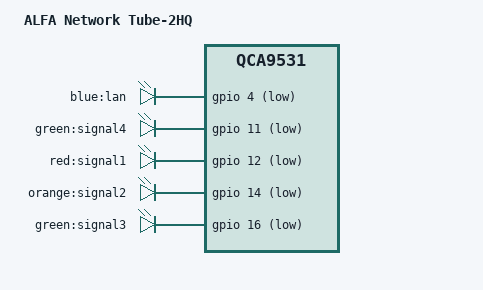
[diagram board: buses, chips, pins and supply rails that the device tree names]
// SPDX-License-Identifier: GPL-2.0-or-later OR MIT

#include "qca9531_alfa-network_r36a.dtsi"

/ {
	model = "ALFA Network Tube-2HQ";
	compatible = "alfa-network,tube-2hq", "qca,qca9531";

	aliases {
		led-boot = &led_signal4;
		led-failsafe = &led_signal4;
		led-upgrade = &led_signal4;
	};

	leds {
		compatible = "gpio-leds";

		pinctrl-names = "default";
		pinctrl-0 = <&enable_gpio4 &enable_gpio16>;

		lan {
			label = "blue:lan";
			gpios = <&gpio 4 GPIO_ACTIVE_LOW>;
		};

		led_signal4: signal4 {
			label = "green:signal4";
			gpios = <&gpio 11 GPIO_ACTIVE_LOW>;
		};

		signal1 {
			label = "red:signal1";
			gpios = <&gpio 12 GPIO_ACTIVE_LOW>;
		};

		signal2 {
			label = "orange:signal2";
			gpios = <&gpio 14 GPIO_ACTIVE_LOW>;
		};

		signal3 {
			label = "green:signal3";
			gpios = <&gpio 16 GPIO_ACTIVE_LOW>;
		};
	};
};

&eth0 {
	nvmem-cells = <&macaddr_art_1002>;
	nvmem-cell-names = "mac-address";

	mac-address-increment = <(-1)>;
};

&eth1 {
	compatible = "syscon", "simple-mfd";
};

&usb0 {
	status = "disabled";
};

&usb_phy {
	status = "disabled";
};
